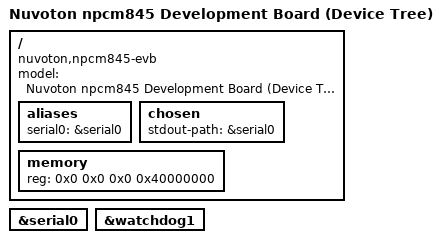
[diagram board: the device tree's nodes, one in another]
/dts-v1/;
#include "nuvoton-npcm845.dtsi"
/ {
	model = "Nuvoton npcm845 Development Board (Device Tree)";
	compatible = "nuvoton,npcm845-evb", "nuvoton,npcm845";
	aliases {
		serial0 = &serial0;
	};
	chosen {
		stdout-path = &serial0;
	};
	memory {
		reg = <0x0 0x0 0x0 0x40000000>;
	};
};
&serial0 {
	status = "okay";
};
&watchdog1 {
	status = "okay";
};
